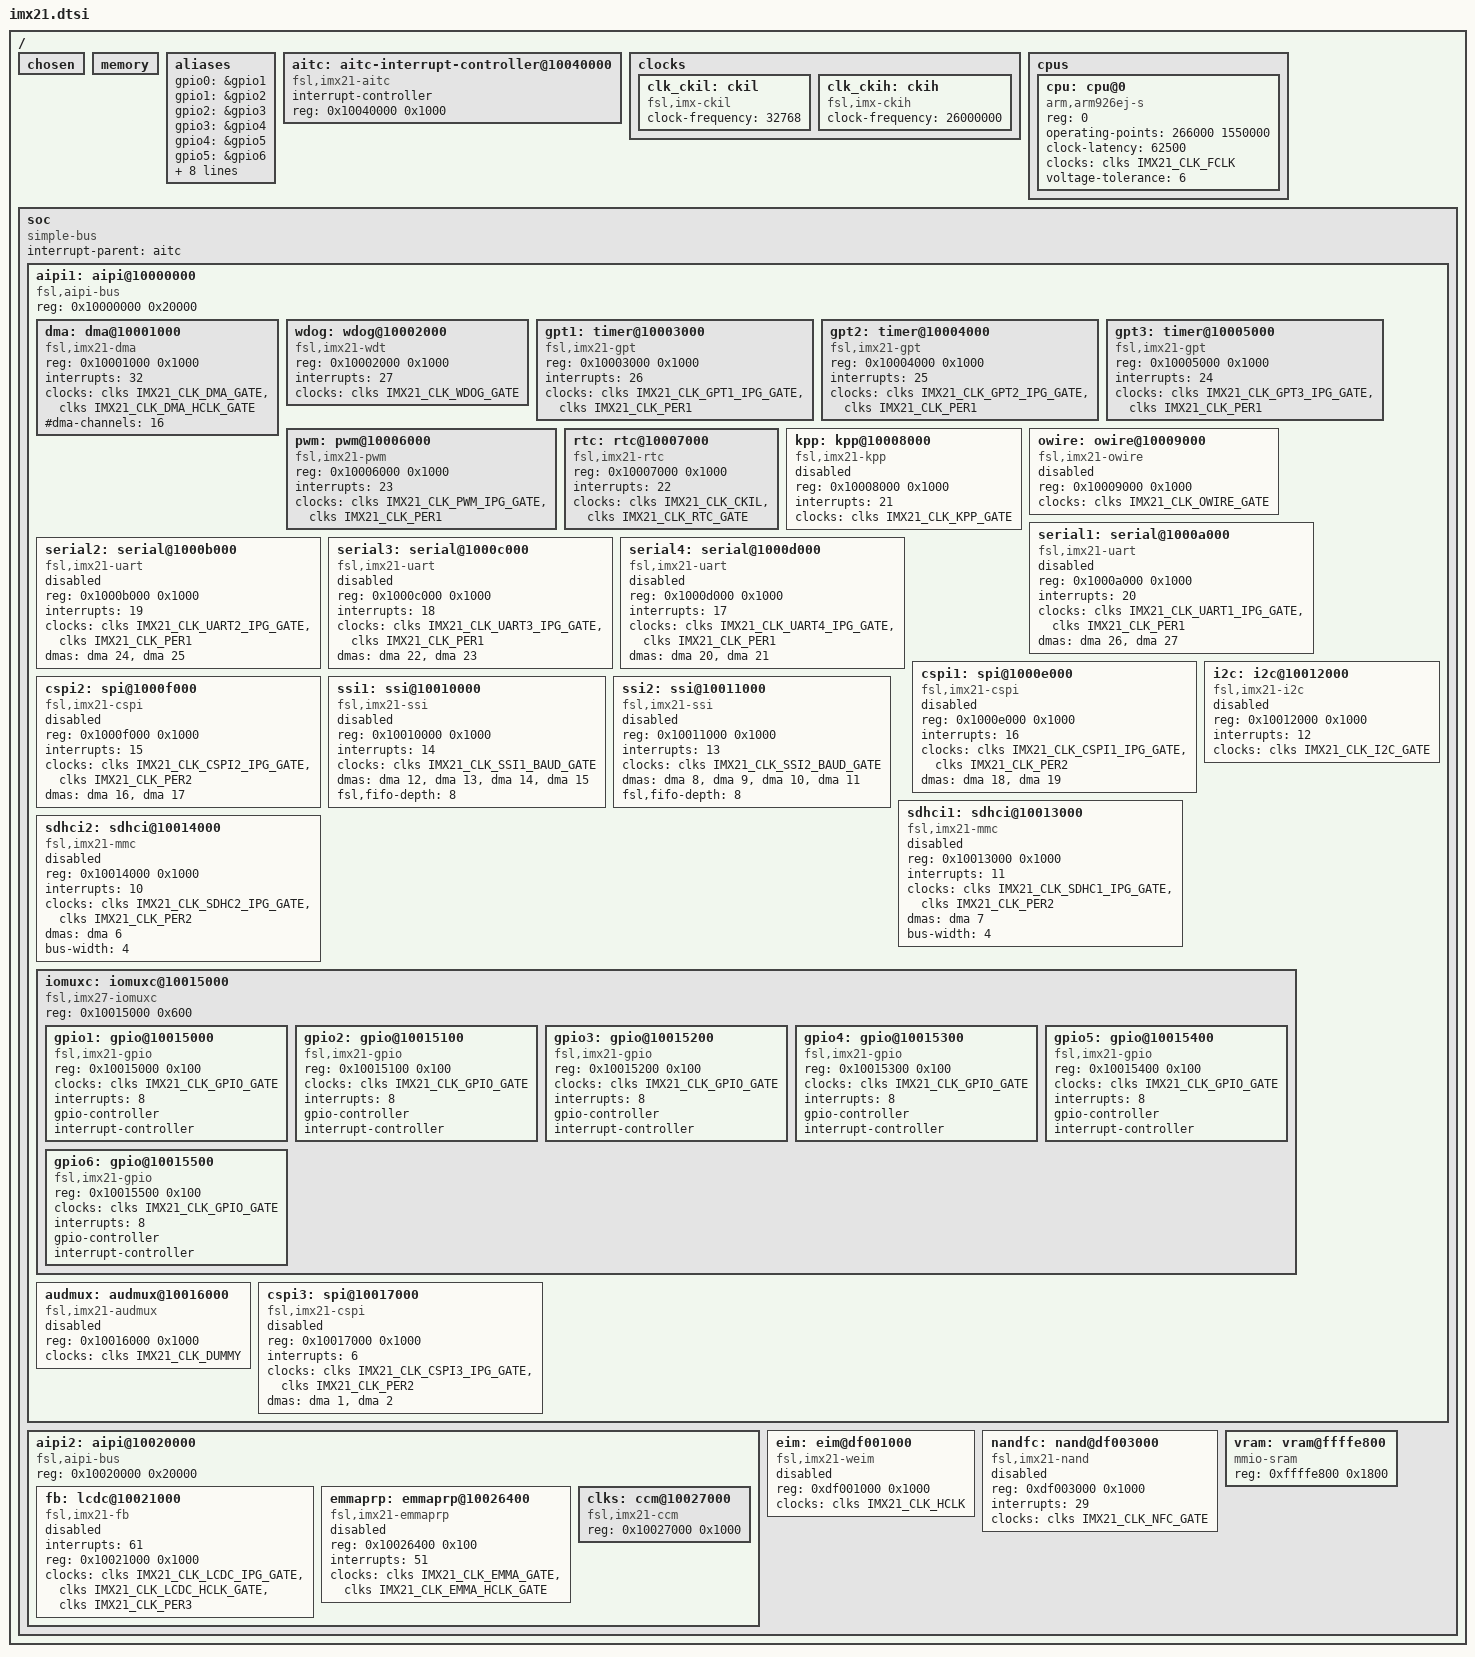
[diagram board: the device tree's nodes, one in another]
// SPDX-License-Identifier: GPL-2.0-or-later
/* Author: Alexander Shiyan <shc_work@mail.ru> */

#include "imx21-pinfunc.h"

#include <dt-bindings/clock/imx21-clock.h>

/ {
	#address-cells = <1>;
	#size-cells = <1>;

	chosen {};

	memory {
		device_type = "memory";
	};

	aliases {
		gpio0 = &gpio1;
		gpio1 = &gpio2;
		gpio2 = &gpio3;
		gpio3 = &gpio4;
		gpio4 = &gpio5;
		gpio5 = &gpio6;
		i2c0 = &i2c;
		serial0 = &serial1;
		serial1 = &serial2;
		serial2 = &serial3;
		serial3 = &serial4;
		spi0 = &cspi1;
		spi1 = &cspi2;
		spi2 = &cspi3;
	};

	aitc: aitc-interrupt-controller@10040000 {
		compatible = "fsl,imx21-aitc", "fsl,avic";
		interrupt-controller;
		#interrupt-cells = <1>;
		reg = <0x10040000 0x1000>;
	};

	clocks {
		clk_ckil: ckil {
			compatible = "fsl,imx-ckil", "fixed-clock";
			#clock-cells = <0>;
			clock-frequency = <32768>;
		};

		clk_ckih: ckih {
			compatible = "fsl,imx-ckih", "fixed-clock";
			#clock-cells = <0>;
			clock-frequency = <26000000>;
		};
	};

	cpus {
		#size-cells = <0>;
		#address-cells = <1>;

		cpu: cpu@0 {
			device_type = "cpu";
			reg = <0>;
			compatible = "arm,arm926ej-s";
			operating-points = <266000 1550000>;
			clock-latency = <62500>;
			clocks = <&clks IMX21_CLK_FCLK>;
			voltage-tolerance = <6>;
		};
	};

	soc {
		#address-cells = <1>;
		#size-cells = <1>;
		compatible = "simple-bus";
		interrupt-parent = <&aitc>;
		ranges;

		aipi1: aipi@10000000 {
			compatible = "fsl,aipi-bus", "simple-bus";
			#address-cells = <1>;
			#size-cells = <1>;
			reg = <0x10000000 0x20000>;
			ranges;

			dma: dma@10001000 {
				compatible = "fsl,imx21-dma";
				reg = <0x10001000 0x1000>;
				interrupts = <32>;
				clocks = <&clks IMX21_CLK_DMA_GATE>,
					 <&clks IMX21_CLK_DMA_HCLK_GATE>;
				clock-names = "ipg", "ahb";
				#dma-cells = <1>;
				#dma-channels = <16>;
			};

			wdog: wdog@10002000 {
				compatible = "fsl,imx21-wdt";
				reg = <0x10002000 0x1000>;
				interrupts = <27>;
				clocks = <&clks IMX21_CLK_WDOG_GATE>;
			};

			gpt1: timer@10003000 {
				compatible = "fsl,imx21-gpt";
				reg = <0x10003000 0x1000>;
				interrupts = <26>;
				clocks = <&clks IMX21_CLK_GPT1_IPG_GATE>,
					 <&clks IMX21_CLK_PER1>;
				clock-names = "ipg", "per";
			};

			gpt2: timer@10004000 {
				compatible = "fsl,imx21-gpt";
				reg = <0x10004000 0x1000>;
				interrupts = <25>;
				clocks = <&clks IMX21_CLK_GPT2_IPG_GATE>,
					 <&clks IMX21_CLK_PER1>;
				clock-names = "ipg", "per";
			};

			gpt3: timer@10005000 {
				compatible = "fsl,imx21-gpt";
				reg = <0x10005000 0x1000>;
				interrupts = <24>;
				clocks = <&clks IMX21_CLK_GPT3_IPG_GATE>,
					 <&clks IMX21_CLK_PER1>;
				clock-names = "ipg", "per";
			};

			pwm: pwm@10006000 {
				#pwm-cells = <2>;
				compatible = "fsl,imx21-pwm", "fsl,imx1-pwm";
				reg = <0x10006000 0x1000>;
				interrupts = <23>;
				clocks = <&clks IMX21_CLK_PWM_IPG_GATE>,
					 <&clks IMX21_CLK_PER1>;
				clock-names = "ipg", "per";
			};

			rtc: rtc@10007000 {
				compatible = "fsl,imx21-rtc";
				reg = <0x10007000 0x1000>;
				interrupts = <22>;
				clocks = <&clks IMX21_CLK_CKIL>,
					 <&clks IMX21_CLK_RTC_GATE>;
				clock-names = "ref", "ipg";
			};

			kpp: kpp@10008000 {
				compatible = "fsl,imx21-kpp";
				reg = <0x10008000 0x1000>;
				interrupts = <21>;
				clocks = <&clks IMX21_CLK_KPP_GATE>;
				status = "disabled";
			};

			owire: owire@10009000 {
				compatible = "fsl,imx21-owire";
				reg = <0x10009000 0x1000>;
				clocks = <&clks IMX21_CLK_OWIRE_GATE>;
				status = "disabled";
			};

			serial1: serial@1000a000 {
				compatible = "fsl,imx21-uart";
				reg = <0x1000a000 0x1000>;
				interrupts = <20>;
				clocks = <&clks IMX21_CLK_UART1_IPG_GATE>,
					 <&clks IMX21_CLK_PER1>;
				clock-names = "ipg", "per";
				dmas = <&dma 26>, <&dma 27>;
				dma-names = "rx", "tx";
				status = "disabled";
			};

			serial2: serial@1000b000 {
				compatible = "fsl,imx21-uart";
				reg = <0x1000b000 0x1000>;
				interrupts = <19>;
				clocks = <&clks IMX21_CLK_UART2_IPG_GATE>,
					 <&clks IMX21_CLK_PER1>;
				clock-names = "ipg", "per";
				dmas = <&dma 24>, <&dma 25>;
				dma-names = "rx", "tx";
				status = "disabled";
			};

			serial3: serial@1000c000 {
				compatible = "fsl,imx21-uart";
				reg = <0x1000c000 0x1000>;
				interrupts = <18>;
				clocks = <&clks IMX21_CLK_UART3_IPG_GATE>,
					 <&clks IMX21_CLK_PER1>;
				clock-names = "ipg", "per";
				dmas = <&dma 22>, <&dma 23>;
				dma-names = "rx", "tx";
				status = "disabled";
			};

			serial4: serial@1000d000 {
				compatible = "fsl,imx21-uart";
				reg = <0x1000d000 0x1000>;
				interrupts = <17>;
				clocks = <&clks IMX21_CLK_UART4_IPG_GATE>,
					 <&clks IMX21_CLK_PER1>;
				clock-names = "ipg", "per";
				dmas = <&dma 20>, <&dma 21>;
				dma-names = "rx", "tx";
				status = "disabled";
			};

			cspi1: spi@1000e000 {
				#address-cells = <1>;
				#size-cells = <0>;
				compatible = "fsl,imx21-cspi";
				reg = <0x1000e000 0x1000>;
				interrupts = <16>;
				clocks = <&clks IMX21_CLK_CSPI1_IPG_GATE>,
					 <&clks IMX21_CLK_PER2>;
				clock-names = "ipg", "per";
				dmas = <&dma 18>, <&dma 19>;
				dma-names = "rx", "tx";
				status = "disabled";
			};

			cspi2: spi@1000f000 {
				#address-cells = <1>;
				#size-cells = <0>;
				compatible = "fsl,imx21-cspi";
				reg = <0x1000f000 0x1000>;
				interrupts = <15>;
				clocks = <&clks IMX21_CLK_CSPI2_IPG_GATE>,
					 <&clks IMX21_CLK_PER2>;
				clock-names = "ipg", "per";
				dmas = <&dma 16>, <&dma 17>;
				dma-names = "rx", "tx";
				status = "disabled";
			};

			ssi1: ssi@10010000 {
				#sound-dai-cells = <0>;
				compatible ="fsl,imx21-ssi";
				reg = <0x10010000 0x1000>;
				interrupts = <14>;
				clocks = <&clks IMX21_CLK_SSI1_BAUD_GATE>;
				dmas = <&dma 12>, <&dma 13>, <&dma 14>, <&dma 15>;
				dma-names = "rx0", "tx0", "rx1", "tx1";
				fsl,fifo-depth = <8>;
				status = "disabled";
			};

			ssi2: ssi@10011000 {
				#sound-dai-cells = <0>;
				compatible = "fsl,imx21-ssi";
				reg = <0x10011000 0x1000>;
				interrupts = <13>;
				clocks = <&clks IMX21_CLK_SSI2_BAUD_GATE>;
				dmas = <&dma 8>, <&dma 9>, <&dma 10>, <&dma 11>;
				dma-names = "rx0", "tx0", "rx1", "tx1";
				fsl,fifo-depth = <8>;
				status = "disabled";
			};

			i2c: i2c@10012000 {
				#address-cells = <1>;
				#size-cells = <0>;
				compatible = "fsl,imx21-i2c";
				reg = <0x10012000 0x1000>;
				interrupts = <12>;
				clocks = <&clks IMX21_CLK_I2C_GATE>;
				status = "disabled";
			};

			sdhci1: sdhci@10013000 {
				compatible = "fsl,imx21-mmc";
				reg = <0x10013000 0x1000>;
				interrupts = <11>;
				clocks = <&clks IMX21_CLK_SDHC1_IPG_GATE>,
					 <&clks IMX21_CLK_PER2>;
				clock-names = "ipg", "per";
				dmas = <&dma 7>;
				dma-names = "rx-tx";
				bus-width = <4>;
				status = "disabled";
			};

			sdhci2: sdhci@10014000 {
				compatible = "fsl,imx21-mmc";
				reg = <0x10014000 0x1000>;
				interrupts = <10>;
				clocks = <&clks IMX21_CLK_SDHC2_IPG_GATE>,
					 <&clks IMX21_CLK_PER2>;
				clock-names = "ipg", "per";
				dmas = <&dma 6>;
				dma-names = "rx-tx";
				bus-width = <4>;
				status = "disabled";
			};

			iomuxc: iomuxc@10015000 {
				compatible = "fsl,imx27-iomuxc";
				reg = <0x10015000 0x600>;
				#address-cells = <1>;
				#size-cells = <1>;
				ranges;

				gpio1: gpio@10015000 {
					compatible = "fsl,imx21-gpio";
					reg = <0x10015000 0x100>;
					clocks = <&clks IMX21_CLK_GPIO_GATE>;
					interrupts = <8>;
					gpio-controller;
					#gpio-cells = <2>;
					interrupt-controller;
					#interrupt-cells = <2>;
				};

				gpio2: gpio@10015100 {
					compatible = "fsl,imx21-gpio";
					reg = <0x10015100 0x100>;
					clocks = <&clks IMX21_CLK_GPIO_GATE>;
					interrupts = <8>;
					gpio-controller;
					#gpio-cells = <2>;
					interrupt-controller;
					#interrupt-cells = <2>;
				};

				gpio3: gpio@10015200 {
					compatible = "fsl,imx21-gpio";
					reg = <0x10015200 0x100>;
					clocks = <&clks IMX21_CLK_GPIO_GATE>;
					interrupts = <8>;
					gpio-controller;
					#gpio-cells = <2>;
					interrupt-controller;
					#interrupt-cells = <2>;
				};

				gpio4: gpio@10015300 {
					compatible = "fsl,imx21-gpio";
					reg = <0x10015300 0x100>;
					clocks = <&clks IMX21_CLK_GPIO_GATE>;
					interrupts = <8>;
					gpio-controller;
					#gpio-cells = <2>;
					interrupt-controller;
					#interrupt-cells = <2>;
				};

				gpio5: gpio@10015400 {
					compatible = "fsl,imx21-gpio";
					reg = <0x10015400 0x100>;
					clocks = <&clks IMX21_CLK_GPIO_GATE>;
					interrupts = <8>;
					gpio-controller;
					#gpio-cells = <2>;
					interrupt-controller;
					#interrupt-cells = <2>;
				};

				gpio6: gpio@10015500 {
					compatible = "fsl,imx21-gpio";
					reg = <0x10015500 0x100>;
					clocks = <&clks IMX21_CLK_GPIO_GATE>;
					interrupts = <8>;
					gpio-controller;
					#gpio-cells = <2>;
					interrupt-controller;
					#interrupt-cells = <2>;
				};
			};

			audmux: audmux@10016000 {
				compatible = "fsl,imx21-audmux";
				reg = <0x10016000 0x1000>;
				clocks = <&clks IMX21_CLK_DUMMY>;
				clock-names = "audmux";
				status = "disabled";
			};

			cspi3: spi@10017000 {
				#address-cells = <1>;
				#size-cells = <0>;
				compatible = "fsl,imx21-cspi";
				reg = <0x10017000 0x1000>;
				interrupts = <6>;
				clocks = <&clks IMX21_CLK_CSPI3_IPG_GATE>,
					 <&clks IMX21_CLK_PER2>;
				clock-names = "ipg", "per";
				dmas = <&dma 1>, <&dma 2>;
				dma-names = "rx", "tx";
				status = "disabled";
			};
		};

		aipi2: aipi@10020000 {
			compatible = "fsl,aipi-bus", "simple-bus";
			#address-cells = <1>;
			#size-cells = <1>;
			reg = <0x10020000 0x20000>;
			ranges;


			fb: lcdc@10021000 {
				compatible = "fsl,imx21-fb";
				interrupts = <61>;
				reg = <0x10021000 0x1000>;
				clocks = <&clks IMX21_CLK_LCDC_IPG_GATE>,
					 <&clks IMX21_CLK_LCDC_HCLK_GATE>,
					 <&clks IMX21_CLK_PER3>;
				clock-names = "ipg", "ahb", "per";
				status = "disabled";
			};

			emmaprp: emmaprp@10026400 {
				compatible = "fsl,imx21-emmaprp";
				reg = <0x10026400 0x100>;
				interrupts = <51>;
				clocks = <&clks IMX21_CLK_EMMA_GATE>,
					 <&clks IMX21_CLK_EMMA_HCLK_GATE>;
				clock-names = "ipg", "ahb";
				status = "disabled";
			};

			clks: ccm@10027000{
				compatible = "fsl,imx21-ccm";
				reg = <0x10027000 0x1000>;
				#clock-cells = <1>;
			};
		};

		eim: eim@df001000 {
			#address-cells = <2>;
			#size-cells = <1>;
			compatible = "fsl,imx21-weim", "fsl,imx1-weim";
			reg = <0xdf001000 0x1000>;
			clocks = <&clks IMX21_CLK_HCLK>;
			ranges = <
				0 0 0xc8000000 0x04000000
				1 0 0xcc000000 0x04000000
				2 0 0xd0000000 0x01000000
				3 0 0xd1000000 0x01000000
				4 0 0xd2000000 0x01000000
				5 0 0xd3000000 0x01000000
			>;
			status = "disabled";
		};

		nandfc: nand@df003000 {
			#address-cells = <1>;
			#size-cells = <1>;
			compatible = "fsl,imx21-nand";
			reg = <0xdf003000 0x1000>;
			interrupts = <29>;
			clocks = <&clks IMX21_CLK_NFC_GATE>;
			status = "disabled";
		};

		vram: vram@ffffe800 {
			compatible = "mmio-sram";
			reg = <0xffffe800 0x1800>;
		};
	};
};
